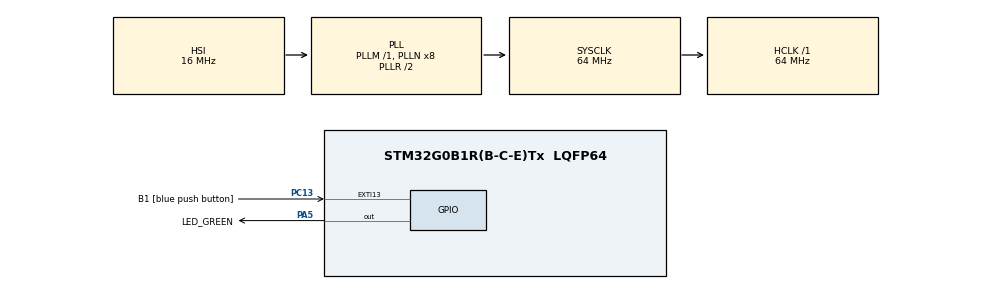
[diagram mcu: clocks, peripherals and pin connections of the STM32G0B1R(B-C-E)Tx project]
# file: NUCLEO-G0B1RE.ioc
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Mcu.Family=STM32G0
Mcu.Name=STM32G0B1R(B-C-E)Tx
Mcu.Package=LQFP64
PA13.GPIO_Label=TMS
PA13.Signal=SYS_SWDIO
PA14-BOOT0.GPIO_Label=TCK
PA14-BOOT0.Signal=SYS_SWCLK
PA2.GPIO_Label=USART2_TX [STLK_TX]
PA2.Signal=USART2_TX
PA3.GPIO_Label=USART2_RX [STLK_RX]
PA3.Signal=USART2_RX
PA5.GPIO_Label=LED_GREEN
PA5.GPIO_Speed=GPIO_SPEED_FREQ_HIGH
PA5.Signal=GPIO_Output
PC13.GPIO_Label=B1 [blue push button]
PC13.Signal=GPXTI13
PC14-OSC32_IN\ (PC14).Signal=RCC_OSC32_IN
PC15-OSC32_OUT\ (PC15).Signal=RCC_OSC32_OUT
PF0-OSC_IN\ (PF0).GPIO_Label=MCO
PF0-OSC_IN\ (PF0).Signal=RCC_OSC_IN
ProjectManager.HeapSize=0x200
ProjectManager.StackSize=0x400
ProjectManager.TargetToolchain=STM32CubeIDE
RCC.ADCFreq_Value=64000000
RCC.AHBFreq_Value=64000000
RCC.CortexFreq_Value=64000000
RCC.EXTERNAL_CLOCK_VALUE=12288000
RCC.HCLKFreq_Value=64000000
RCC.HSE_VALUE=8000000
RCC.HSI48_VALUE=48000000
RCC.HSI_VALUE=16000000
RCC.LSE_VALUE=32768
RCC.SYSCLKFreq_VALUE=64000000
RCC.SYSCLKSource=RCC_SYSCLKSOURCE_PLLCLK
RCC.USBFreq_Value=48000000
RCC.VCOOutputFreq_Value=128000000
board=NUCLEO-G0B1RE

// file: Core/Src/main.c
/* USER CODE BEGIN Header */
/**
  ******************************************************************************
  * @file           : main.c
  * @brief          : Main program body
  ******************************************************************************
  * @attention
  *
  * Copyright (c) 2024 STMicroelectronics.
  * All rights reserved.
  *
  * This software is licensed under terms that can be found in the LICENSE file
  * in the root directory of this software component.
  * If no LICENSE file comes with this software, it is provided AS-IS.
  *
  ******************************************************************************
  */
/* USER CODE END Header */
#include "main.h"

void SystemClock_Config(void);
static void MX_GPIO_Init(void);

int main(void)
{

  /* USER CODE BEGIN 1 */
	uint8_t u8_DataSw;

  /* USER CODE END 1 */

  /* MCU Configuration--------------------------------------------------------*/

  /* Reset of all peripherals, Initializes the Flash interface and the Systick. */
  HAL_Init();

  /* Configure the system clock */
  SystemClock_Config();

  /* Initialize all configured peripherals */
  MX_GPIO_Init();

  /* Infinite loop */
  /* USER CODE BEGIN WHILE */
	while (1) {
		u8_DataSw = HAL_GPIO_ReadPin(B1_GPIO_Port, B1_Pin);
    /* USER CODE END WHILE */

    /* USER CODE BEGIN 3 */
		HAL_GPIO_WritePin(LED_GREEN_GPIO_Port, LED_GREEN_Pin, u8_DataSw);
	}
  /* USER CODE END 3 */
}

void SystemClock_Config(void)
{
  RCC_OscInitTypeDef RCC_OscInitStruct = {0};
  RCC_ClkInitTypeDef RCC_ClkInitStruct = {0};

  /** Configure the main internal regulator output voltage
  */
  HAL_PWREx_ControlVoltageScaling(PWR_REGULATOR_VOLTAGE_SCALE1);

  /** Initializes the RCC Oscillators according to the specified parameters
  * in the RCC_OscInitTypeDef structure.
  */
  RCC_OscInitStruct.OscillatorType = RCC_OSCILLATORTYPE_HSI;
  RCC_OscInitStruct.HSIState = RCC_HSI_ON;
  RCC_OscInitStruct.HSIDiv = RCC_HSI_DIV1;
  RCC_OscInitStruct.HSICalibrationValue = RCC_HSICALIBRATION_DEFAULT;
  RCC_OscInitStruct.PLL.PLLState = RCC_PLL_ON;
  RCC_OscInitStruct.PLL.PLLSource = RCC_PLLSOURCE_HSI;
  RCC_OscInitStruct.PLL.PLLM = RCC_PLLM_DIV1;
  RCC_OscInitStruct.PLL.PLLN = 8;
  RCC_OscInitStruct.PLL.PLLP = RCC_PLLP_DIV2;
  RCC_OscInitStruct.PLL.PLLQ = RCC_PLLQ_DIV2;
  RCC_OscInitStruct.PLL.PLLR = RCC_PLLR_DIV2;
  if (HAL_RCC_OscConfig(&RCC_OscInitStruct) != HAL_OK)
  {
    Error_Handler();
  }

  /** Initializes the CPU, AHB and APB buses clocks
  */
  RCC_ClkInitStruct.ClockType = RCC_CLOCKTYPE_HCLK|RCC_CLOCKTYPE_SYSCLK
                              |RCC_CLOCKTYPE_PCLK1;
  RCC_ClkInitStruct.SYSCLKSource = RCC_SYSCLKSOURCE_PLLCLK;
  RCC_ClkInitStruct.AHBCLKDivider = RCC_SYSCLK_DIV1;
  RCC_ClkInitStruct.APB1CLKDivider = RCC_HCLK_DIV1;

  if (HAL_RCC_ClockConfig(&RCC_ClkInitStruct, FLASH_LATENCY_2) != HAL_OK)
  {
    Error_Handler();
  }
}

static void MX_GPIO_Init(void)
{
  GPIO_InitTypeDef GPIO_InitStruct = {0};

  /* GPIO Ports Clock Enable */
  __HAL_RCC_GPIOC_CLK_ENABLE();
  __HAL_RCC_GPIOF_CLK_ENABLE();
  __HAL_RCC_GPIOA_CLK_ENABLE();

  /*Configure GPIO pin Output Level */
  HAL_GPIO_WritePin(LED_GREEN_GPIO_Port, LED_GREEN_Pin, GPIO_PIN_RESET);

  /*Configure GPIO pin : B1_Pin */
  GPIO_InitStruct.Pin = B1_Pin;
  GPIO_InitStruct.Mode = GPIO_MODE_IT_RISING;
  GPIO_InitStruct.Pull = GPIO_NOPULL;
  HAL_GPIO_Init(B1_GPIO_Port, &GPIO_InitStruct);

  /*Configure GPIO pins : USART2_TX_Pin USART2_RX_Pin */
  GPIO_InitStruct.Pin = USART2_TX_Pin|USART2_RX_Pin;
  GPIO_InitStruct.Mode = GPIO_MODE_AF_PP;
  GPIO_InitStruct.Pull = GPIO_NOPULL;
  GPIO_InitStruct.Speed = GPIO_SPEED_FREQ_LOW;
  GPIO_InitStruct.Alternate = GPIO_AF1_USART2;
  HAL_GPIO_Init(GPIOA, &GPIO_InitStruct);

  /*Configure GPIO pin : LED_GREEN_Pin */
  GPIO_InitStruct.Pin = LED_GREEN_Pin;
  GPIO_InitStruct.Mode = GPIO_MODE_OUTPUT_PP;
  GPIO_InitStruct.Pull = GPIO_NOPULL;
  GPIO_InitStruct.Speed = GPIO_SPEED_FREQ_HIGH;
  HAL_GPIO_Init(LED_GREEN_GPIO_Port, &GPIO_InitStruct);

}

void Error_Handler(void)
{
  __disable_irq();
  while (1)
  {
  }
}
